# M55M1 register map
File version: 1.0
Registers are 32-bit, read-write, reset 0x0 unless marked. A register's access mark holds for its fields unless they carry their own. Offsets are from the block's base; [hi:lo] are bit positions; {n}, {i} and the like mark numbered series; 'fields as' and 'values as' point back to an identical list.

## EMAC0 (part 2 of 2) — EMAC Register Map
Base 0x40208000
Same registers: EMAC0_NS 0x50208000
0x704 Sub_Second_Increment — Register 449 (Sub-Second Increment Register)
  [7:0] SSINC — Sub-second Increment Value. The value programmed in this field is accumulated every clock cycle with the contents of the sub-second register. For example, when PTP clock is 50 MHz (period is 20 ns), you should program 20 (0x14) when the System Time-Nanoseconds register has an accuracy of 1 ns (TSCTRLSSR bit is set). When TSCTRLSSR is clear, the Nanoseconds register has a resolution of ~0.465ns. In this case, you should program a value of 43 (0x2B) that is derived by 20ns/0.465.
0x708 System_Time_Seconds ro — Register 450 (System Time - Seconds Register)
  [31:0] TSS — Timestamp Second. The value in this field indicates the current value in seconds of the System Time maintained by the MAC.
0x70C System_Time_Nanoseconds ro — Register 451 (System Time - Nanoseconds Register)
  [30:0] TSSS — Timestamp Sub Seconds. The value in this field has the sub second representation of time, with an accuracy of 0.46 ns. When bit 9 (TSCTRLSSR) is set in Register 448 (Timestamp Control Register), each bit represents 1 ns and the maximum value is 0x3B9A_C9FF, after which it rolls-over to zero.
0x710 System_Time_Seconds_Update — Register 452 (System Time - Seconds Update Register)
  [31:0] TSS — Timestamp Second. The value in this field indicates the time in seconds to be initialized or added to the system time.
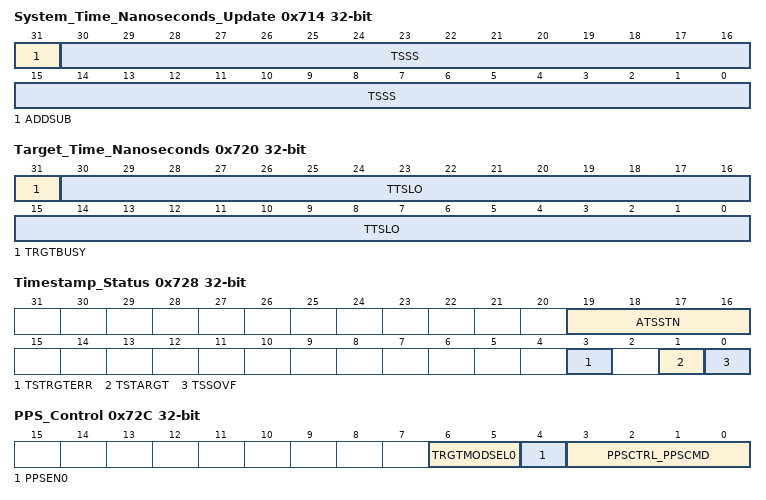
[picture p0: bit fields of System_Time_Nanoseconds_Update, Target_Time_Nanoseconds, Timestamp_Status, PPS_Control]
0x714 System_Time_Nanoseconds_Update — Register 453 (System Time - Nanoseconds Update Register)
  [31] ADDSUB — Add or subtract time. When this bit is set, the time value is subtracted with the contents of the update register. When this bit is reset, the time value is added with the contents of the update register.
  [30:0] TSSS — Timestamp Sub Second. The value in this field has the sub second representation of time, with an accuracy of 0.46 ns. When bit 9 (TSCTRLSSR) is set in Register 448 (Timestamp Control Register), each bit represents 1 ns and the programmed value should not exceed 0x3B9A_C9FF.
0x718 Timestamp_Addend — Register 454 (Timestamp Addend Register)
  [31:0] TSAR — Timestamp Addend Register. This field indicates the 32-bit time value to be added to the Accumulator register to achieve time synchronization.
0x71C Target_Time_Seconds — Register 455 (Target Time Seconds Register)
  [31:0] TSTR — Target Time Seconds Register. This register stores the time in seconds. When the timestamp value matches or exceeds both Target Timestamp registers, then based on Bits [6:5] of Register 459 (PPS Control Register), the MAC starts or stops the PPS signal output and generates an interrupt (if enabled).
0x720 Target_Time_Nanoseconds — Register 456 (Target Time Nanoseconds Register)
  [31] TRGTBUSY ro — Target Time Register Busy (read only). The MAC sets this bit when the PPSCMD field (Bits [3:0]) in Register 459 (PPS Control Register) is programmed to 010 or 011. Programming the PPSCMD field to 010 or 011, instructs the MAC to synchronize the Target Time Registers to the PTP clock domain. The MAC clears this bit after synchronizing the Target Time Registers to the PTP clock domain The application must not update the Target Time Registers when this bit is read as 1. Otherwise, the synchronization of the previous programmed time gets corrupted. This bit is reserved when the Enable Flexible Pulse-Per-Second Output feature is not selected.
  [30:0] TTSLO — Target Timestamp Low Register. This register stores the time in (signed) nanoseconds. When the value of the timestamp matches the both Target Timestamp registers, then based on the TRGTMODSEL0 field (Bits [6:5]) in Register 459 (PPS Control Register), the MAC starts or stops the PPS signal output and generates an interrupt (if enabled). This value should not exceed 0x3B9A_C9FF when TSCTRLSSR is set in the Timestamp control register. The actual start or stop time of the PPS signal output may have an error margin up to one unit of sub-second increment value.
0x724 System_Time_Higher_Word_Seconds — Register 457 (System Time - Higher Word Seconds Register)
  [15:0] TSHWR — Timestamp Higher Word Register. This field contains the most significant 16-bits of the timestamp seconds value. The register is directly written to initialize the value. This register is incremented when there is an overflow from the 32-bits of the System Time - Seconds register.
0x728 Timestamp_Status ro — Register 458 (Timestamp Status Register)
  [19:16] ATSSTN — Auxiliary Timestamp Snapshot Trigger Identifier. These bits identify the Auxiliary trigger inputs for which the timestamp available in the Auxiliary Snapshot Register is applicable. When more than one bit is set at the same time, it means that corresponding auxiliary triggers were sampled at the same clock. These bits are applicable only if the number of Auxiliary snapshots is more than one. One bit is assigned for each trigger as shown in the following list: Bit 16: Auxiliary trigger 0. Bit 17: Auxiliary trigger 1. Bit 18: Auxiliary trigger 2. Bit 19: Auxiliary trigger 3. The software can read this register to find the triggers that are set when the timestamp is taken.
  [3] TSTRGTERR — Timestamp Target Time Error. This bit is set when the target time, being programmed in Target Time Registers, is already elapsed. This bit is cleared when read by the application.
  [1] TSTARGT — Timestamp Target Time Reached. When set, this bit indicates that the value of system time is greater or equal to the value specified in the Register 455 (Target Time Seconds Register) and Register 456 (Target Time Nanoseconds Register).
  [0] TSSOVF — Timestamp Seconds Overflow. When set, this bit indicates that the seconds value of the timestamp (when supporting version 2 format) has overflowed beyond 32'hFFFF_FFFF.
0x72C PPS_Control — Register 459 (PPS Control Register)
  [6:5] TRGTMODSEL0 — Target Time Register Mode for PPS0 Output. This field indicates the Target Time registers (register 455 and 456) mode for PPS0 output signal:
    0=Indicates that the Target Time registers are programmed only for generating the interrupt event; 2=Indicates that the Target Time registers are programmed for generating the interrupt event and starting or stopping the generation of the PPS0 output signal; 3=Indicates that the Target Time registers are programmed only for starting or stopping the generation of the PPS0 output signal. No interrupt is asserted
  [4] PPSEN0 — Flexible PPS Output Mode Enable. When set low, Bits [3:0] function as PPSCTRL (backward compatible). When set high, Bits [3:0] function as PPSCMD.
  [3:0] PPSCTRL_PPSCMD — PPSCTRL0 or PPSCMD0. PPSCTRL0: PPS0 Output Frequency Control. This field controls the frequency of the PPS0 output signal. The default value of PPSCTRL is 0000, and the PPS output is 1 pulse every second. For other values of PPSCTRL, the PPS output becomes a generated clock of following frequencies:
    0=The binary rollover is 1 Hz, and the digital rollover is 0.5 Hz. No Command; 1=The binary rollover is 2 Hz, and the digital rollover is 1 Hz. START Single Pulse This command generates single pulse rising at the start point defined in Target Time Registers (register 455 and 456) and of a duration defined in the PPS0 Width Register; 2=The binary rollover is 4 Hz, and the digital rollover is 2 Hz. START Pulse Train This command generates the train of pulses rising at the start point defined in the Target Time Registers and of a duration defined in the PPS0 Width Register and repeated at interval defined in the PPS Interval Register. By default, the PPS pulse train is free-running unless stopped by 'STOP Pulse train at time' or 'STOP Pulse Train immediately' commands; 3=The binary rollover is 8 Hz, and the digital rollover is 4 Hz. Cancel START; 4=The binary rollover is 16 Hz, and the digital rollover is 8 Hz. STOP Pulse train at time This command stops the train of pulses initiated by the START Pulse Train command (PPSCMD = 0010) after the time programmed in the Target Time registers elapses; 5=STOP Pulse Train immediately This command immediately stops the train of pulses initiated by the START Pulse Train command (PPSCMD = 0010); 6=Cancel STOP Pulse Train. This command cancels the STOP pulse train at time command if the programmed stop time has not elapsed. The PPS pulse train becomes free-running on the successful execution of this command; 15=The binary rollover is 32.768 kHz, and the digital rollover is 16.384 kHz
0x760 PPS0_Interval — Register 472 (PPS0 Interval Register)
  [31:0] PPSINT — PPS0 Output Signal Interval. These bits store the interval between the rising edges of PPS0 signal output in terms of units of sub-second increment value. You need to program one value less than the required interval. For example, if the PTP reference clock is 50 MHz (period of 20ns), and desired interval between rising edges of PPS0 signal output is 100ns (that is, five units of sub-second increment value), then you should program value 4 (5 -1) in this register.
0x764 PPS0_Width — Register 473 (PPS0 Width Register)
  [31:0] PPSWIDTH — PPS0 Output Signal Width. These bits store the width between the rising edge and corresponding falling edge of the PPS0 signal output in terms of units of sub-second increment value. You need to program one value less than the required interval. For example, if PTP reference clock is 50 MHz (period of 20ns), and desired width between the rising and corresponding falling edges of PPS0 signal output is 80ns (that is, four units of sub-second increment value), then you should program value 3 (4-1) in this register. Note: The value programmed in this register must be lesser than the value programmed in Register 472 (PPS0 Interval Register).
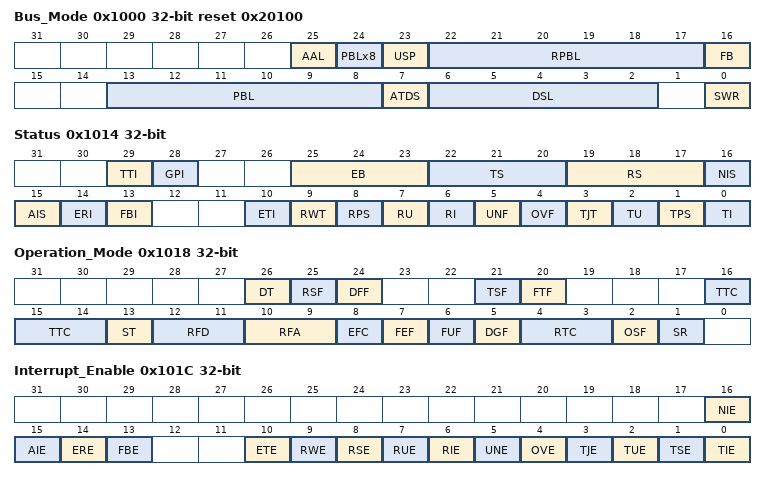
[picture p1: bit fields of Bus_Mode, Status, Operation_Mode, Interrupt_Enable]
0x1000 Bus_Mode reset 0x20100 — Register 1000 (Bus Mode Register)
  [25] AAL — Address Aligned Beats. When this bit is set high and the FB bit is equal to 1, the AHB interface generates all bursts aligned to the start address LS bits. If the FB bit is equal to 0, the first burst (accessing the data buffer's start address) is not aligned, but subsequent bursts are aligned to the address.
  [24] PBLx8 — PBLx8 Mode. When set high, this bit multiplies the programmed PBL value (Bits [22:17] and Bits [13:8]) eight times. Therefore, the DMA transfers the data in 8, 16, 32, 64, 128, and 256 beats depending on the PBL value.
  [23] USP — Use Separate PBL. When set high, this bit configures the Rx DMA to use the value configured in Bits [22:17] as PBL. The PBL value in Bits [13:8] is applicable only to the Tx DMA operations. When reset to low, the PBL value in Bits [13:8] is applicable for both DMA engines.
  [22:17] RPBL — Rx DMA PBL. This field indicates the maximum number of beats to be transferred in one Rx DMA transaction. This is the maximum value that is used in a single block Read or Write. The Rx DMA always attempts to burst as specified in the RPBL bit each time it starts a Burst transfer on the host bus. You can program RPBL with values of 1, 2, 4, 8, 16, and 32. Any other value results in undefined behavior. This field is valid and applicable only when USP is set high.
  [16] FB — Fixed Burst. This bit controls whether the AHB Master interface performs fixed burst transfers or not. When set, the AHB interface uses only SINGLE, INCR4, INCR8, or INCR16 during start of the normal burst transfers. When reset, the AHB interface uses SINGLE and INCR burst transfer operations.
  [13:8] PBL — Programmable Burst Length. These bits indicate the maximum number of beats to be transferred in one DMA transaction. This is the maximum value that is used in a single block Read or Write. The DMA always attempts to burst as specified in PBL each time it starts a Burst transfer on the host bus. PBL can be programmed with permissible values of 1, 2, 4, 8, 16, and 32. Any other value results in undefined behavior. When USP is set high, this PBL value is applicable only for Tx DMA transactions. If the number of beats to be transferred is more than 32, then perform the following steps: 1. Set the PBLx8 mode. 2. Set the PBL. For example, if the maximum number of beats to be transferred is 64, then first set PBLx8 to 1 and then set PBL to 8. The PBL values have the following limitation: The maximum number of possible beats (PBL) is limited by the size of the Tx FIFO and Rx FIFO in the MTL layer and the data bus width on the DMA. The FIFO has a constraint that the maximum beat supported is half the depth of the FIFO, except when specified. For different data bus widths and FIFO sizes, the valid PBL range (including x8 mode) is provided in the following list. If the PBL is common for both transmit and receive DMA, the minimum Rx FIFO and Tx FIFO depths must be considered. Note: In the half-duplex mode, the valid PBL range specified in the following list is applicable only for Tx FIFO. * 32-Bit Data Bus Width. 128 Bytes FIFO Depth: In the full-duplex mode, the valid PBL range is 16 or less. In the half-duplex mode, the valid PBL range is 8 or less for the 10 or 100 Mbps mode. 256 Bytes FIFO Depth: In the full-duplex mode and the half-duplex (10 or 100 Mbps) modes, the valid PBL range is 32 or less. 512 Bytes FIFO Depth: In the full-duplex mode and the half-duplex (10 or 100 Mbps) modes, the valid PBL range is 64 or less. 1 Kbytes FIFO Depth: In the full-duplex mode, the valid PBL range is 128 or less. In the half-duplex mode, the valid PBL range is 128 or less in the 10 or 100 Mbps mode and 64 or less in the 1000 Mbps mode. 2 Kbytes and Higher FIFO Depth: All PBL values are supported in the full-duplex mode and half-duplex modes. * 64-Bit Data Bus Width. 128 Bytes FIFO Depth: In the full-duplex mode, the valid PBL range is 8 or less. In the half-duplex mode, the valid PBL range is 4 or less for the 10 or 100 Mbps mode. 256 Bytes FIFO Depth: In the full-duplex mode and the half-duplex (10 or 100 Mbps) modes, the valid PBL range is 16 or less. 512 Bytes FIFO Depth: In the full-duplex mode and the half-duplex (10 or 100 Mbps) modes, the valid PBL range is 32 or less. 1 Kbytes FIFO Depth: In the full-duplex mode, the valid PBL range is 64 or less. In the half-duplex mode, the valid PBL range is 64 or less in the 10 or 100 Mbps mode and 32 or less in the 1000-Mbps mode. 2 Kbytes FIFO Depth: In the full-duplex mode and the half-duplex (10 or 100 Mbps) modes, the valid PBL range is 128 or less. 4 Kbytes and Higher FIFO Depth: All PBL values are supported in the full-duplex and half-duplex modes. * 128-Bit Data Bus Width. 128 Bytes FIFO Depth: In the full-duplex mode, the valid PBL range is 4 or less. In the half-duplex mode, the valid PBL range is 2 or less for the 10 or 100 Mbps mode. 256 Bytes FIFO Depth: In the full-duplex mode and the half-duplex (10 or 100 Mbps) modes, the valid PBL range is 8 or less. 512 Bytes FIFO Depth: In the full-duplex mode and the half-duplex (10 or 100 Mbps) modes, the valid PBL range is 16 or less. 1 Kbytes FIFO Depth: In the full-duplex mode, the valid PBL range is 32 or less. In the half-duplex mode, the valid PBL range is 32 or less in the 10 or 100 Mbps mode and 16 or less in the 1000-Mbps mode. 2 Kbytes FIFO Depth: In the full-duplex mode and the half-duplex (10 or 100 Mbps) modes, the valid PBL range is 64 or less. 4 Kbytes FIFO Depth: In the full-duplex mode and the half-duplex (10 or 100 Mbps) modes, the valid PBL range is 128 or less. 8 Kbytes and Higher FIFO Depth: All PBL values are supported in the full-duplex and half-duplex modes.
  [7] ATDS — Alternate Descriptor Size. When set, the size of the alternate descriptor increases to 32 bytes (8 DWORDS). This is required when the Advanced Timestamp feature or the IPC Full Offload Engine (Type 2) is enabled in the receiver. The enhanced descriptor is not required if the Advanced Timestamp and IPC Full Checksum Offload (Type 2) features are not enabled. In such cases, you can use the 16 bytes descriptor to save 4 bytes of memory. . When reset, the descriptor size reverts back to 4 DWORDs (16 bytes). This bit preserves the backward compatibility for the descriptor size. In versions prior to 3.50a, the descriptor size is 16 bytes for both normal and enhanced descriptors. In version 3.50a, descriptor size is increased to 32 bytes because of the Advanced Timestamp and IPC Full Checksum Offload Engine (Type 2) features.
  [6:2] DSL — Descriptor Skip Length. This bit specifies the number of Word, Dword, or Lword (depending on the 32-bit, 64-bit, or 128-bit bus) to skip between two unchained descriptors. The address skipping starts from the end of current descriptor to the start of next descriptor. When the DSL value is equal to zero, the descriptor table is taken as contiguous by the DMA in Ring mode.
  [0] SWR — Software Reset. When this bit is set, the MAC DMA Controller resets the logic and all internal registers of the MAC. It is cleared automatically after the reset operation has completed in all of the EMAC clock domains. Before reprogramming any register of the EMAC, you should read a zero (0) value in this bit. Note: The Software reset function is driven only by this bit. The reset operation is completed only when all resets in all active clock domains are de-asserted. Therefore, it is essential that all the PHY inputs clocks (applicable for the selected PHY interface) are present for the software reset completion.
0x1004 Transmit_Poll_Demand — Register 1001 (Transmit Poll Demand Register)
  [31:0] TPD — Transmit Poll Demand. When these bits are written with any value, the DMA reads the current descriptor pointed to by Register 1018 (Current Host Transmit Descriptor Register). If that descriptor is not available (owned by the Host), the transmission returns to the Suspend state and the Bit 2 (TU) of Register 1005 (Status Register) is asserted. If the descriptor is available, the transmission resumes.
0x1008 Receive_Poll_Demand — Register 1002 (Receive Poll Demand Register)
  [31:0] RPD — Receive Poll Demand. When these bits are written with any value, the DMA reads the current descriptor pointed to by Register 1019 (Current Host Receive Descriptor Register). If that descriptor is not available (owned by the Host), the reception returns to the Suspended state and the Bit 7 (RU) of Register 1005 (Status Register) is not asserted. If the descriptor is available, the Rx DMA returns to the active state.
0x100C Receive_Descriptor_List_Address — Register 1003 (Receive Descriptor List Address Register)
  [31:3] RDESLA_64_bit — Start of Receive List. This field contains the base address of the first descriptor in the Receive Descriptor list. The LSB bits (2:0) for 64-bit bus width are ignored and are internally taken as all-zero by the DMA. Therefore, these LSB bits are read-only (RO).
0x1010 Transmit_Descriptor_List_Address — Register 1004 (Transmit Descriptor List Address Register)
  [31:3] TDESLA_64_bit — Start of Transmit List. This field contains the base address of the first descriptor in the Transmit Descriptor list. The LSB bits (2:0) for 64-bit bus width are ignored and are internally taken as all-zero by the DMA. Therefore, these LSB bits are read-only (RO).
0x1014 Status — Register 1005 (Status Register)
  [29] TTI ro — Timestamp Trigger Interrupt (read only). This bit indicates an interrupt event in the Timestamp Generator block of EMAC. The software must read the corresponding registers in the EMAC to get the exact cause of interrupt and clear its source to reset this bit to 1'b0. When this bit is high, the interrupt signal from the EMAC subsystem is high. This bit is applicable only when the IEEE 1588 Timestamp feature is enabled. Otherwise, this bit is reserved.
  [28] GPI ro — GMAC PMT Interrupt (read only). This bit indicates an interrupt event in the PMT module of the EMAC. The software must read the PMT Control and Status Register in the MAC to get the exact cause of interrupt and clear its source to reset this bit to 1'b0. The interrupt signal from the EMAC subsystem is high when this bit is high. This bit is applicable only when the Power Management feature is enabled. Otherwise, this bit is reserved.
  [25:23] EB ro — Error Bits (read only). This field indicates the type of error that caused a Bus Error, for example, error response on the AHB interface. This field is valid only when Bit 13 (FBI) is set. This field does not generate an interrupt. Note: 001 and 010 are reserved.
    0=Error during Rx DMA Write Data Transfer; 3=Error during Tx DMA Read Data Transfer; 4=Error during Rx DMA Descriptor Write Access; 5=Error during Tx DMA Descriptor Write Access; 6=Error during Rx DMA Descriptor Read Access; 7=Error during Tx DMA Descriptor Read Access
  [22:20] TS ro — Transmit Process State (read only). This field indicates the Transmit DMA FSM state. This field does not generate an interrupt.
  [19:17] RS ro — Received Process State (read only). This field indicates the Receive DMA FSM state. This field does not generate an interrupt.
  [16] NIS — Normal Interrupt Summary. Normal Interrupt Summary bit value is the logical OR of the following when the corresponding interrupt bits are enabled in Register 1007 (Interrupt Enable Register): Register 1005[0]: Transmit Interrupt. Register 1005[2]: Transmit Buffer Unavailable. Register 1005[6]: Receive Interrupt. Register 1005[14]: Early Receive Interrupt. Only unmasked bits (interrupts for which interrupt enable is set in Register 1007) affect the Normal Interrupt Summary bit. This is a sticky bit and must be cleared (by writing 1 to this bit) each time a corresponding bit, which causes NIS to be set, is cleared.
  [15] AIS — Abnormal Interrupt Summary. Abnormal Interrupt Summary bit value is the logical OR of the following when the corresponding interrupt bits are enabled in Register 1007 (Interrupt Enable Register): Register 1005[1]: Transmit Process Stopped. Register 1005[3]: Transmit Jabber Timeout. Register 1005[4]: Receive FIFO Overflow. Register 1005[5]: Transmit Underflow. Register 1005[7]: Receive Buffer Unavailable. Register 1005[8]: Receive Process Stopped. Register 1005[9]: Receive Watchdog Timeout. Register 1005[10]: Early Transmit Interrupt. Register 1005[13]: Fatal Bus Error. Only unmasked bits affect the Abnormal Interrupt Summary bit. This is a sticky bit and must be cleared each time a corresponding bit, which causes AIS to be set, is cleared.
  [14] ERI — Early Receive Interrupt. This bit indicates that the DMA filled the first data buffer of the packet. This bit is cleared when the software writes 1 to this bit or Bit 6 (RI) of this register is set (whichever occurs earlier).
  [13] FBI — Fatal Bus Error Interrupt. This bit indicates that a bus error occurred, as described in Bits [25:23]. When this bit is set, the corresponding DMA engine disables all of its bus accesses.
  [10] ETI — Early Transmit Interrupt. This bit indicates that the frame to be transmitted is fully transferred to the MTL Transmit FIFO.
  [9] RWT — Receive Watchdog Timeout. When set, this bit indicates that the Receive Watchdog Timer expired while receiving the current frame and the current frame is truncated after the watchdog timeout.
  [8] RPS — Receive Process Stopped. This bit is asserted when the Receive Process enters the Stopped state.
  [7] RU — Receive Buffer Unavailable. This bit indicates that the host owns the Next Descriptor in the Receive List and the DMA cannot acquire it. The Receive Process is suspended. To resume processing Receive descriptors, the host should change the ownership of the descriptor and issue a Receive Poll Demand command. If no Receive Poll Demand is issued, the Receive Process resumes when the next recognized incoming frame is received. This bit is set only when the previous Receive Descriptor is owned by the DMA.
  [6] RI — Receive Interrupt. This bit indicates that the frame reception is complete. When reception is complete, the Bit 31 of RDES1 (Disable Interrupt on Completion) is reset in the last Descriptor, and the specific frame status information is updated in the descriptor. The reception remains in the Running state.
  [5] UNF — Transmit Underflow. This bit indicates that the Transmit Buffer had an Underflow during frame transmission. Transmission is suspended and an Underflow Error TDES0[1] is set.
  [4] OVF — Receive Overflow. This bit indicates that the Receive Buffer had an Overflow during frame reception. If the partial frame is transferred to the application, the overflow status is set in RDES0[11].
  [3] TJT — Transmit Jabber Timeout. This bit indicates that the Transmit Jabber Timer expired, which happens when the frame size exceeds 2,048 (10,240 bytes when the Jumbo frame is enabled). When the Jabber Timeout occurs, the transmission process is aborted and placed in the Stopped state. This causes the Transmit Jabber Timeout TDES0[14] flag to assert.
  [2] TU — Transmit Buffer Unavailable. This bit indicates that the host owns the Next Descriptor in the Transmit List and the DMA cannot acquire it. Transmission is suspended. Bits [22:20] explain the Transmit Process state transitions. To resume processing Transmit descriptors, the host should change the ownership of the descriptor by setting TDES0[31] and then issue a Transmit Poll Demand command.
  [1] TPS — Transmit Process Stopped. This bit is set when the transmission is stopped.
  [0] TI — Transmit Interrupt. This bit indicates that the frame transmission is complete. When transmission is complete, Bit 31 (OWN) of TDES0 is reset, and the specific frame status information is updated in the descriptor.
0x1018 Operation_Mode — Register 1006 (Operation Mode Register)
  [26] DT — Disable Dropping of TCP/IP Checksum Error Frames. When this bit is set, the MAC does not drop the frames which only have errors detected by the Receive Checksum Offload engine. Such frames do not have any errors (including FCS error) in the Ethernet frame received by the MAC but have errors only in the encapsulated payload. When this bit is reset, all error frames are dropped if the FEF bit is reset. If the IPC Full Checksum Offload Engine (Type 2) is disabled, this bit is reserved (RO with value 1'b0).
  [25] RSF — Receive Store and Forward. When this bit is set, the MTL reads a frame from the Rx FIFO only after the complete frame has been written to it, ignoring the RTC bits. When this bit is reset, the Rx FIFO operates in the cut-through mode, subject to the threshold specified by the RTC bits
  [24] DFF — Disable Flushing of Received Frames. When this bit is set, the Rx DMA does not flush any frames because of the unavailability of receive descriptors or buffers as it does normally when this bit is reset.
  [21] TSF — Transmit Store and Forward. When this bit is set, transmission starts when a full frame resides in the MTL Transmit FIFO. When this bit is set, the TTC values specified in Bits [16:14] are ignored. This bit should be changed only when the transmission is stopped.
  [20] FTF — Flush Transmit FIFO. When this bit is set, the transmit FIFO controller logic is reset to its default values and thus all data in the Tx FIFO is lost or flushed. This bit is cleared internally when the flushing operation is completed. The Operation Mode register should not be written to until this bit is cleared. The data which is already accepted by the MAC transmitter is not flushed. It is scheduled for transmission and results in underflow and runt frame transmission. Note: The flush operation is complete only when the Tx FIFO is emptied of its contents and all the pending Transmit Status of the transmitted frames are accepted by the host. To complete this flush operation, the PHY transmit clock is required to be active.
  [16:14] TTC — Transmit Threshold Control. These bits control the threshold level of the MTL Transmit FIFO. Transmission starts when the frame size within the MTL Transmit FIFO is larger than the threshold. In addition, full frames with a length less than the threshold are also transmitted. These bits are used only when Bit 21 (TSF) is reset.
    0=64 bytes; 1=128 bytes; 2=192 bytes; 3=256 bytes; 4=40 bytes; 5=32 bytes; 6=24 bytes; 7=16 bytes
  [13] ST — Start or Stop Transmission Command. When this bit is set, transmission is placed in the Running state, and the DMA checks the Transmit List at the current position for a frame to be transmitted. Descriptor acquisition is attempted either from the current position in the list, which is the Transmit List Base Address set by Register 1004 (Transmit Descriptor List Address Register), or from the position retained when transmission was stopped previously. If the DMA does not own the current descriptor, transmission enters the Suspended state and Bit 2 (Transmit Buffer Unavailable) of Register 1005 (Status Register) is set. The Start Transmission command is effective only when transmission is stopped. If the command is issued before setting Register 1004 (Transmit Descriptor List Address Register), then the DMA behavior is unpredictable. When this bit is reset, the transmission process is placed in the Stopped state after completing the transmission of the current frame. The Next Descriptor position in the Transmit List is saved, and it becomes the current position when transmission is restarted. To change the list address, you need to program Register 1004 (Transmit Descriptor List Address Register) with a new value when this bit is reset. The new value is considered when this bit is set again. The stop transmission command is effective only when the transmission of the current frame is complete or the transmission is in the Suspended state.
  [12:11] RFD — Threshold for Deactivating Flow Control. These bits control the threshold (Fill-level of Rx FIFO) at which the flow control is de-asserted after activation. The de-assertion is effective only after flow control is asserted. If the Rx FIFO is 8 Kbytes or more, an additional bit (RFD_2) is used for more threshold levels as described in Bit 22. These bits are reserved and read-only when the Rx FIFO depth is less than 4 Kbytes. Note: For proper flow control, the value programmed in the RFD_2, RFD fields should be equal to or more than the value programmed in the RFA_2, RFA fields.
    {v}=Full minus {v+1} Kbytes, that is, FULL - {v+1} Kbytes (v=0..3)
  [10:9] RFA — Threshold for Activating Flow Control. These bits control the threshold (Fill level of Rx FIFO) at which the flow control is activated. These values are applicable only to Rx FIFOs of 4 Kbytes or more and when Bit 8 (EFC) is set high. If the Rx FIFO is 8 Kbytes or more, an additional Bit (RFA_2) is used for more threshold levels as described in Bit 23. These bits are reserved and read-only when the depth of Rx FIFO is less than 4 Kbytes. Note: When FIFO size is exactly 4 Kbytes, although the EMAC allows you to program the value of these bits to 11, the software should not program these bits to 2'b11. The value 2'b11 means flow control on FIFO empty condition.
    values as RFD
  [8] EFC — Enable HW Flow Control. When this bit is set, the flow control signal operation based on the fill-level of Rx FIFO is enabled. When reset, the flow control operation is disabled. This bit is not used (reserved and always reset) when the Rx FIFO is less than 4 Kbytes.
  [7] FEF — Forward Error Frames. When this bit is reset, the Rx FIFO drops frames with error status (CRC error, collision error, GMII_ER, giant frame, watchdog timeout, or overflow). However, if the start byte (write) pointer of a frame is already transferred to the read controller side (in Threshold mode), then the frame is not dropped. When the FEF bit is set, all frames except runt error frames are forwarded to the DMA. If the Bit 25 (RSF) is set and the Rx FIFO overflows when a partial frame is written, then the frame is dropped irrespective of the FEF bit setting. However, if the Bit 25 (RSF) is reset and the Rx FIFO overflows when a partial frame is written, then a partial frame may be forwarded to the DMA.
  [6] FUF — Forward Undersized Good Frames. When set, the Rx FIFO forwards Undersized frames (frames with no Error and length less than 64 bytes) including pad-bytes and CRC.
  [5] DGF — Drop Giant Frames. When set, the MAC drops the received giant frames in the Rx FIFO, that is, frames that are larger than the computed giant frame limit. When reset, the MAC does not drop the giant frames in the Rx FIFO.
  [4:3] RTC — Receive Threshold Control. These two bits control the threshold level of the MTL Receive FIFO. Transfer (request) to DMA starts when the frame size within the MTL Receive FIFO is larger than the threshold. In addition, full frames with length less than the threshold are transferred automatically. These bits are valid only when the RSF bit is zero, and are ignored when the RSF bit is set to 1.
    0=64 bytes; 1=32 bytes; 2=96 bytes; 3=128 bytes
  [2] OSF — Operate on Second Frame. When this bit is set, it instructs the DMA to process the second frame of the Transmit data even before the status for the first frame is obtained.
  [1] SR — Start or Stop Receive. When this bit is set, the Receive process is placed in the Running state. The DMA attempts to acquire the descriptor from the Receive list and processes the incoming frames. The descriptor acquisition is attempted from the current position in the list, which is the address set by Register 1003 (Receive Descriptor List Address Register) or the position retained when the Receive process was previously stopped. If the DMA does not own the descriptor, reception is suspended and Bit 7 (Receive Buffer Unavailable) of Register 1005 (Status Register) is set. The Start Receive command is effective only when the reception has stopped. If the command is issued before setting Register 1003 (Receive Descriptor List Address Register), the DMA behavior is unpredictable. When this bit is cleared, the Rx DMA operation is stopped after the transfer of the current frame. The next descriptor position in the Receive list is saved and becomes the current position after the Receive process is restarted. The Stop Receive command is effective only when the Receive process is in either the Running (waiting for receive packet) or in the Suspended state.
0x101C Interrupt_Enable — Register 1007 (Interrupt Enable Register)
  [16] NIE — Normal Interrupt Summary Enable. When this bit is set, normal interrupt summary is enabled. When this bit is reset, normal interrupt summary is disabled. This bit enables the following interrupts in Register 1005 (Status Register): Register 1005[0]: Transmit Interrupt. Register 1005[2]: Transmit Buffer Unavailable. Register 1005[6]: Receive Interrupt. Register 1005[14]: Early Receive Interrupt
  [15] AIE — Abnormal Interrupt Summary Enable. When this bit is set, abnormal interrupt summary is enabled. When this bit is reset, the abnormal interrupt summary is disabled. This bit enables the following interrupts in Register 1005 (Status Register): Register 1005[1]: Transmit Process Stopped. Register 1005[3]: Transmit Jabber Timeout. Register 1005[4]: Receive Overflow. Register 1005[5]: Transmit Underflow. Register 1005[7]: Receive Buffer Unavailable. Register 1005[8]: Receive Process Stopped. Register 1005[9]: Receive Watchdog Timeout. Register 1005[10]: Early Transmit Interrupt. Register 1005[13]: Fatal Bus Error
  [14] ERE — Early Receive Interrupt Enable. When this bit is set with Normal Interrupt Summary Enable (Bit 16), the Early Receive Interrupt is enabled. When this bit is reset, the Early Receive Interrupt is disabled.
  [13] FBE — Fatal Bus Error Enable. When this bit is set with Abnormal Interrupt Summary Enable (Bit 15), the Fatal Bus Error Interrupt is enabled. When this bit is reset, the Fatal Bus Error Enable Interrupt is disabled.
  [10] ETE — Early Transmit Interrupt Enable. When this bit is set with an Abnormal Interrupt Summary Enable (Bit 15), the Early Transmit Interrupt is enabled. When this bit is reset, the Early Transmit Interrupt is disabled.
  [9] RWE — Receive Watchdog Timeout Enable. When this bit is set with Abnormal Interrupt Summary Enable (Bit 15), the Receive Watchdog Timeout Interrupt is enabled. When this bit is reset, the Receive Watchdog Timeout Interrupt is disabled.
  [8] RSE — Receive Stopped Enable. When this bit is set with Abnormal Interrupt Summary Enable (Bit 15), the Receive Stopped Interrupt is enabled. When this bit is reset, the Receive Stopped Interrupt is disabled.
  [7] RUE — Receive Buffer Unavailable Enable. When this bit is set with Abnormal Interrupt Summary Enable (Bit 15), the Receive Buffer Unavailable Interrupt is enabled. When this bit is reset, the Receive Buffer Unavailable Interrupt is disabled.
  [6] RIE — Receive Interrupt Enable. When this bit is set with Normal Interrupt Summary Enable (Bit 16), the Receive Interrupt is enabled. When this bit is reset, the Receive Interrupt is disabled.
  [5] UNE — Underflow Interrupt Enable. When this bit is set with Abnormal Interrupt Summary Enable (Bit 15), the Transmit Underflow Interrupt is enabled. When this bit is reset, the Underflow Interrupt is disabled.
  [4] OVE — Overflow Interrupt Enable. When this bit is set with Abnormal Interrupt Summary Enable (Bit 15), the Receive Overflow Interrupt is enabled. When this bit is reset, the Overflow Interrupt is disabled.
  [3] TJE — Transmit Jabber Timeout Enable. When this bit is set with Abnormal Interrupt Summary Enable (Bit 15), the Transmit Jabber Timeout Interrupt is enabled. When this bit is reset, the Transmit Jabber Timeout Interrupt is disabled.
  [2] TUE — Transmit Buffer Unavailable Enable. When this bit is set with Normal Interrupt Summary Enable (Bit 16), the Transmit Buffer Unavailable Interrupt is enabled. When this bit is reset, the Transmit Buffer Unavailable Interrupt is disabled.
  [1] TSE — Transmit Stopped Enable. When this bit is set with Abnormal Interrupt Summary Enable (Bit 15), the Transmission Stopped Interrupt is enabled. When this bit is reset, the Transmission Stopped Interrupt is disabled.
  [0] TIE — Transmit Interrupt Enable. When this bit is set with Normal Interrupt Summary Enable (Bit 16), the Transmit Interrupt is enabled. When this bit is reset, the Transmit Interrupt is disabled.
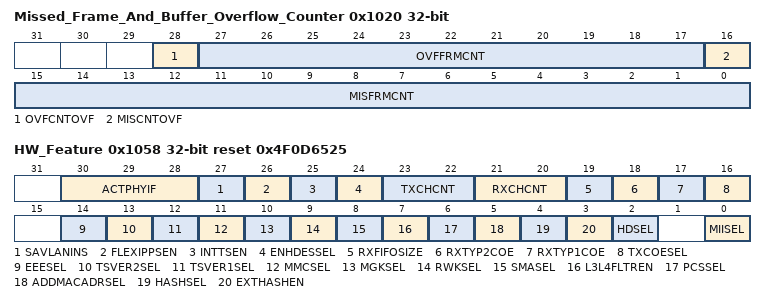
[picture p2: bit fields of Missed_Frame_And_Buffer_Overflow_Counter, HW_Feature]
0x1020 Missed_Frame_And_Buffer_Overflow_Counter ro — Register 1008 (Missed Frame and Buffer Overflow Counter Register)
  [28] OVFCNTOVF — Overflow Bit for FIFO Overflow Counter. This bit is set every time the Overflow Frame Counter (Bits [27:17]) overflows, that is, the Rx FIFO overflows with the overflow frame counter at maximum value. In such a scenario, the overflow frame counter is reset to all-zeros and this bit indicates that the rollover happened.
  [27:17] OVFFRMCNT — Overflow Frame Counter. This field indicates the number of frames missed by the application. This counter is incremented each time the MTL FIFO overflows. The counter is cleared when this register is read with mci_be_i[2] at 1'b1.
  [16] MISCNTOVF — Overflow Bit for Missed Frame Counter. This bit is set every time Missed Frame Counter (Bits [15:0]) overflows, that is, the DMA discards an incoming frame because of the Host Receive Buffer being unavailable with the missed frame counter at maximum value. In such a scenario, the Missed frame counter is reset to all-zeros and this bit indicates that the rollover happened.
  [15:0] MISFRMCNT — Missed Frame Counter. This field indicates the number of frames missed by the controller because of the Host Receive Buffer being unavailable. This counter is incremented each time the DMA discards an incoming frame. The counter is cleared when this register is read with mci_be_i[0] at 1'b1.
0x1024 Receive_Interrupt_Watchdog_Timer — Register 1009 (Receive Interrupt Watchdog Timer Register)
  [7:0] RIWT — RI Watchdog Timer Count. This bit indicates the number of system clock cycles multiplied by 256 for which the watchdog timer is set. The watchdog timer gets triggered with the programmed value after the Rx DMA completes the transfer of a frame for which the RI status bit is not set because of the setting in the corresponding descriptor RDES1[31]. When the watchdog timer runs out, the RI bit is set and the timer is stopped. The watchdog timer is reset when the RI bit is set high because of automatic setting of RI as per RDES1[31] of any received frame.
0x102C AHB_Status ro — Register 1011 (AHB Status Register)
  [0] AXWHSTS — AHB Master Write Channel Status. When high, it indicates that AHB Master's write channel is active and transferring data.
0x1048 Current_Host_Transmit_Descriptor ro — Register 1018 (Current Host Transmit Descriptor Register)
  [31:0] CURTDESAPTR — Host Transmit Descriptor Address Pointer. Cleared on Reset. Pointer updated by the DMA during operation.
0x104C Current_Host_Receive_Descriptor ro — Register 1019 (Current Host Receive Descriptor Register)
  [31:0] CURRDESAPTR — Host Receive Descriptor Address Pointer. Cleared on Reset. Pointer updated by the DMA during operation.
0x1050 Current_Host_Transmit_Buffer_Address ro — Register 1020 (Current Host Transmit Buffer Address Register)
  [31:0] CURTBUFAPTR — Host Transmit Buffer Address Pointer. Cleared on Reset. Pointer updated by the DMA during operation.
0x1054 Current_Host_Receive_Buffer_Address ro — Register 1021 (Current Host Receive Buffer Address Register)
  [31:0] CURRBUFAPTR — Host Receive Buffer Address Pointer. Cleared on Reset. Pointer updated by the DMA during operation.
0x1058 HW_Feature ro reset 0x4F0D6525 — Register 1022 (HW Feature Register)
  [30:28] ACTPHYIF — Active or Selected PHY interface. When you have multiple PHY interfaces in your configuration, this field indicates the sampled value of phy_intf_sel_i during reset de-assertion
    4=RMII
  [27] SAVLANINS — Source Address or VLAN Insertion
  [26] FLEXIPPSEN — Flexible Pulse-Per-Second Output
  [25] INTTSEN — Timestamping with Internal System Time
  [24] ENHDESSEL — Alternate (Enhanced Descriptor)
  [23:22] TXCHCNT — Number of additional Tx channels
  [21:20] RXCHCNT — Number of additional Rx channels
  [19] RXFIFOSIZE — Rx FIFO 2,048 Bytes
  [18] RXTYP2COE — IP Checksum Offload (Type 2) in Rx
  [17] RXTYP1COE — IP Checksum Offload (Type 1) in Rx
  [16] TXCOESEL — Checksum Offload in Tx
  [14] EEESEL — Energy Efficient Ethernet
  [13] TSVER2SEL — IEEE 1588-2008 Advanced Timestamp
  [12] TSVER1SEL — Only IEEE 1588-2002 Timestamp
  [11] MMCSEL — RMON Module
  [10] MGKSEL — PMT Magic Packet
  [9] RWKSEL — PMT Remote Wakeup
  [8] SMASEL — SMA (MDIO) Interface
  [7] L3L4FLTREN — Layer 3 and Layer 4 Filter Feature
  [6] PCSSEL — PCS registers (TBI, SGMII, or RTBI PHY interface)
  [5] ADDMACADRSEL — Multiple MAC Address Registers
  [4] HASHSEL — HASH Filter
  [3] EXTHASHEN — Expanded DA Hash Filter
  [2] HDSEL — Half-Duplex support
  [0] MIISEL — 10 or 100 Mbps support
